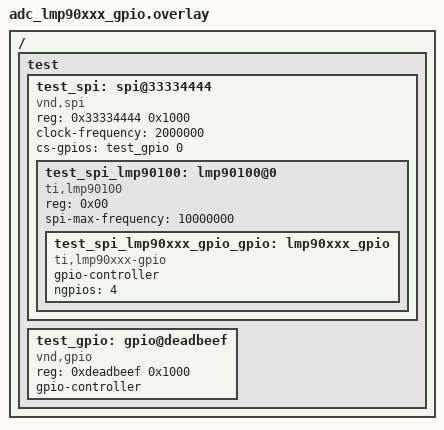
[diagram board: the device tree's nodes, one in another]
/*
 * Copyright (c) 2024 TOKITA Hiroshi
 *
 * SPDX-License-Identifier: Apache-2.0
 */

/ {
	test {
		#address-cells = <1>;
		#size-cells = <1>;

		test_spi: spi@33334444 {
			compatible = "vnd,spi";
			reg = <0x33334444 0x1000>;
			#address-cells = <1>;
			#size-cells = <0>;
			clock-frequency = <2000000>;

			cs-gpios = <&test_gpio 0 0>;
			status = "okay";

			test_spi_lmp90100: lmp90100@0 {
				compatible = "ti,lmp90100";
				reg = <0x00>;
				spi-max-frequency = <10000000>;
				#address-cells = <1>;
				#size-cells = <0>;
				#io-channel-cells = <1>;
				status = "okay";

				test_spi_lmp90xxx_gpio_gpio: lmp90xxx_gpio {
					compatible = "ti,lmp90xxx-gpio";
					gpio-controller;
					ngpios = <4>;
					#gpio-cells = <2>;
				};
			};
		};

		test_gpio: gpio@deadbeef {
			compatible = "vnd,gpio";
			reg = <0xdeadbeef 0x1000>;
			gpio-controller;
			#gpio-cells = <0x2>;
			status = "okay";
		};
	};
};
